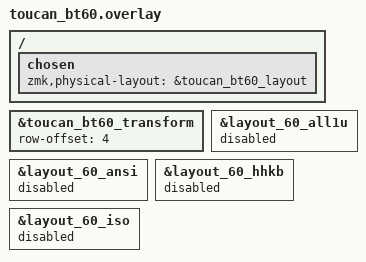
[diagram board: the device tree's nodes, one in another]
#include "../toucan/toucan-bt60-layout.dtsi"

// BT60 kscan rows 1-5 become combined rows 5-9, i.e. dongle positions 42-106.
// Kscan row 0 has no switches on the V2 PCB; its RCs are absent from the map and ignored.
&toucan_bt60_transform {
    row-offset = <4>;
};

/ {
    chosen {
        zmk,physical-layout = &toucan_bt60_layout;
    };
};

// The dongle pushes its selected physical layout to every peripheral as an INDEX
// (split service select_phys_layout -> zmk_physical_layouts_select). The dongle has one
// layout, so it always sends 0. The bt60 board ships four layouts of its own; while they
// are enabled, index 0 is layout_60_all1u and its transform replaces ours, scrambling
// every key. Disable them so toucan_bt60_layout is the only layout, i.e. index 0.
// (The 60% position map tolerates disabled layouts; it stores NULL for them.)
&layout_60_all1u {
    status = "disabled";
};

&layout_60_ansi {
    status = "disabled";
};

&layout_60_hhkb {
    status = "disabled";
};

&layout_60_iso {
    status = "disabled";
};
